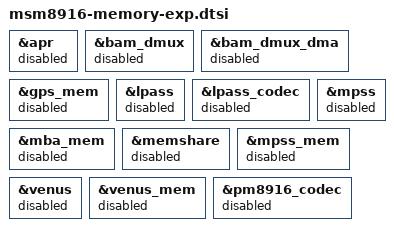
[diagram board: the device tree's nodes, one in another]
&apr {
	status = "disabled";
};

&bam_dmux {
	status = "disabled";
};

&bam_dmux_dma {
	status = "disabled";
};

&gps_mem {
	status = "disabled";
};

&lpass {
	status = "disabled"; /* Controlled by QDSP6 */
};

&lpass_codec {
	status = "disabled";
};

&mba_mem {
	status = "disabled";
};

&memshare {
	status = "disabled";
};

&mpss {
	status = "disabled";
};

&mpss_mem {
	status = "disabled";
};

&venus {
	status = "disabled";
};

&venus_mem {
	status = "disabled";
};

&pm8916_codec {
	status = "disabled";
};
